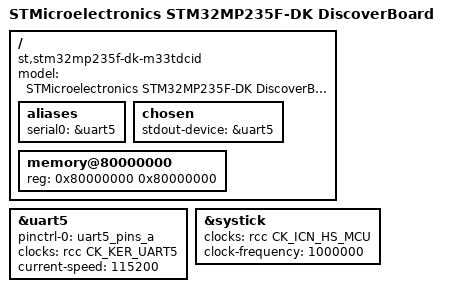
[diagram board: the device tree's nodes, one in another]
/*
 * Copyright (c) 2026, STMicroelectronics - All Rights Reserved
 *
 * SPDX-License-Identifier: Apache-2.0
 */

/dts-v1/;

#include <dt-bindings/clock/stm32mp25-clksrc.h>
#include <dt-bindings/reset/st,stm32mp25-rcc.h>
#include <dt-bindings/memory-attr/memory-attr-arm.h>

#include "stm32mp235.dtsi"
#include "stm32mp23x-ns.dtsi"
#include "stm32mp235f-dk-cm33tdcid-resmem.dtsi"
#include "stm32mp235f-dk-cm33tdcid-ns-rcc.dtsi"
#include "stm32mp23-pinctrl.dtsi"
#include "stm32mp23xxai-pinctrl.dtsi"

/ {
	model = "STMicroelectronics STM32MP235F-DK DiscoverBoard";
	compatible = "st,stm32mp235f-dk-m33tdcid", "st,stm32mp235f-dk", "st,stm32mp235";

	aliases {
		serial0 = &uart5;
	};

	chosen {
		stdout-device = &uart5;
	};

	memory@80000000 {
		device_type = "memory";
		reg = <0x80000000 0x80000000>;
	};
};

&uart5 {
	pinctrl-names = "default";
	pinctrl-0 = <&uart5_pins_a>;
	clocks = <&rcc CK_KER_UART5>;
	current-speed = <115200>;
	status = "okay";
};

&systick {
	clocks = <&rcc CK_ICN_HS_MCU>;
	clock-frequency = <1000000>; /* tick at 1us */
	status = "okay";
};
